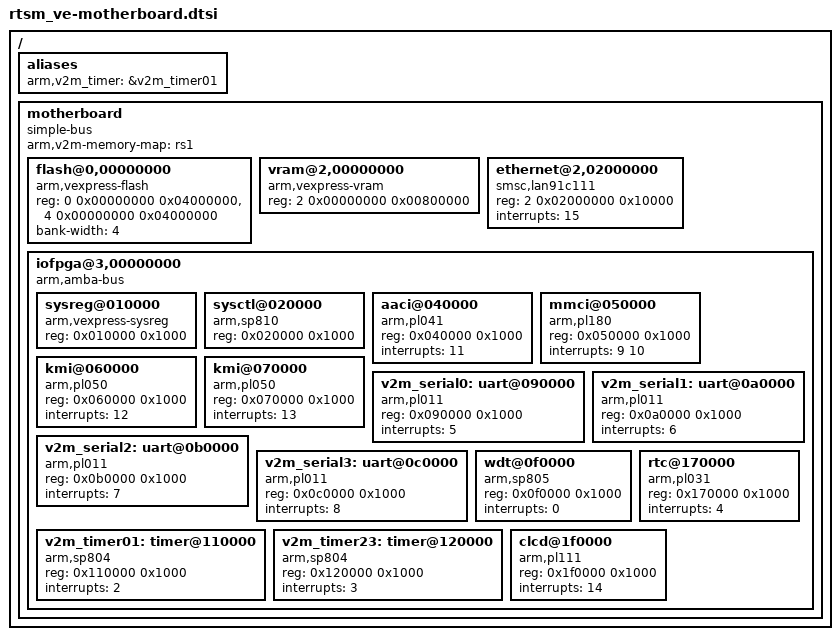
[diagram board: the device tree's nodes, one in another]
/*
 * ARM Ltd. Fast Models
 *
 * Versatile Express (VE) system model
 * Motherboard component
 *
 * VEMotherBoard.lisa
 */

/ {
	aliases {
		arm,v2m_timer = &v2m_timer01;
	};

	motherboard {
		compatible = "simple-bus";
		arm,v2m-memory-map = "rs1";
		#address-cells = <2>; /* SMB chipselect number and offset */
		#size-cells = <1>;
		#interrupt-cells = <1>;

		flash@0,00000000 {
			compatible = "arm,vexpress-flash", "cfi-flash";
			reg = <0 0x00000000 0x04000000>,
			      <4 0x00000000 0x04000000>;
			bank-width = <4>;
		};

		vram@2,00000000 {
			compatible = "arm,vexpress-vram";
			reg = <2 0x00000000 0x00800000>;
		};

		ethernet@2,02000000 {
			compatible = "smsc,lan91c111";
			reg = <2 0x02000000 0x10000>;
			interrupts = <15>;
		};

		iofpga@3,00000000 {
			compatible = "arm,amba-bus", "simple-bus";
			#address-cells = <1>;
			#size-cells = <1>;
			ranges = <0 3 0 0x200000>;

			sysreg@010000 {
				compatible = "arm,vexpress-sysreg";
				reg = <0x010000 0x1000>;
			};

			sysctl@020000 {
				compatible = "arm,sp810", "arm,primecell";
				reg = <0x020000 0x1000>;
			};

			aaci@040000 {
				compatible = "arm,pl041", "arm,primecell";
				reg = <0x040000 0x1000>;
				interrupts = <11>;
			};

			mmci@050000 {
				compatible = "arm,pl180", "arm,primecell";
				reg = <0x050000 0x1000>;
				interrupts = <9 10>;
			};

			kmi@060000 {
				compatible = "arm,pl050", "arm,primecell";
				reg = <0x060000 0x1000>;
				interrupts = <12>;
			};

			kmi@070000 {
				compatible = "arm,pl050", "arm,primecell";
				reg = <0x070000 0x1000>;
				interrupts = <13>;
			};

			v2m_serial0: uart@090000 {
				compatible = "arm,pl011", "arm,primecell";
				reg = <0x090000 0x1000>;
				interrupts = <5>;
			};

			v2m_serial1: uart@0a0000 {
				compatible = "arm,pl011", "arm,primecell";
				reg = <0x0a0000 0x1000>;
				interrupts = <6>;
			};

			v2m_serial2: uart@0b0000 {
				compatible = "arm,pl011", "arm,primecell";
				reg = <0x0b0000 0x1000>;
				interrupts = <7>;
			};

			v2m_serial3: uart@0c0000 {
				compatible = "arm,pl011", "arm,primecell";
				reg = <0x0c0000 0x1000>;
				interrupts = <8>;
			};

			wdt@0f0000 {
				compatible = "arm,sp805", "arm,primecell";
				reg = <0x0f0000 0x1000>;
				interrupts = <0>;
			};

			v2m_timer01: timer@110000 {
				compatible = "arm,sp804", "arm,primecell";
				reg = <0x110000 0x1000>;
				interrupts = <2>;
			};

			v2m_timer23: timer@120000 {
				compatible = "arm,sp804", "arm,primecell";
				reg = <0x120000 0x1000>;
				interrupts = <3>;
			};

			rtc@170000 {
				compatible = "arm,pl031", "arm,primecell";
				reg = <0x170000 0x1000>;
				interrupts = <4>;
			};

			clcd@1f0000 {
				compatible = "arm,pl111", "arm,primecell";
				reg = <0x1f0000 0x1000>;
				interrupts = <14>;
			};
		};
	};
};
